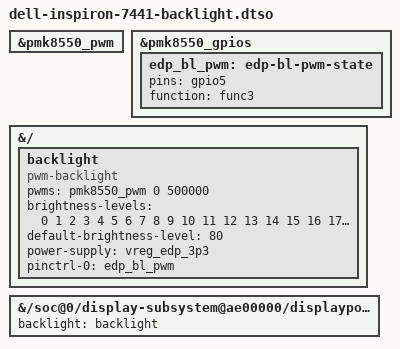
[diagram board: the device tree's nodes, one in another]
// SPDX-License-Identifier: MIT
/*
 * PWM backlight for the Dell Inspiron 14 Plus 7441 (x1e80100).
 *
 * The AUO B140QAX01.H panel advertises PWM brightness control in its DPCD
 * (0x702 = 0x91), so the AUX backlight registers with max_brightness 0 and
 * the stock device tree provides no other brightness path. Firmware already
 * routes PMK8550 GPIO5 to func3; this overlay registers the PWM provider and
 * attaches a pwm-backlight to the existing eDP panel.
 *
 * The 500000 ns period (2 kHz) matches the PMK8550 setup of the
 * x1p42100-lenovo-thinkbook-16.
 */

/dts-v1/;
/plugin/;

&pmk8550_pwm {
	status = "okay";
};

&pmk8550_gpios {
	edp_bl_pwm: edp-bl-pwm-state {
		pins = "gpio5";
		function = "func3";
	};
};

&{/} {
	backlight: backlight {
		compatible = "pwm-backlight";
		pwms = <&pmk8550_pwm 0 500000>;
		brightness-levels = <0 1 2 3 4 5 6 7 8 9 10 11 12 13 14 15 16 17 18 19
				     20 21 22 23 24 25 26 27 28 29 30 31 32 33 34 35 36 37 38 39
				     40 41 42 43 44 45 46 47 48 49 50 51 52 53 54 55 56 57 58 59
				     60 61 62 63 64 65 66 67 68 69 70 71 72 73 74 75 76 77 78 79
				     80 81 82 83 84 85 86 87 88 89 90 91 92 93 94 95 96 97 98 99
				     100>;
		default-brightness-level = <80>;
		power-supply = <&vreg_edp_3p3>;
		pinctrl-names = "default";
		pinctrl-0 = <&edp_bl_pwm>;
	};
};

&{/soc@0/display-subsystem@ae00000/displayport-controller@aea0000/aux-bus/panel} {
	backlight = <&backlight>;
};
